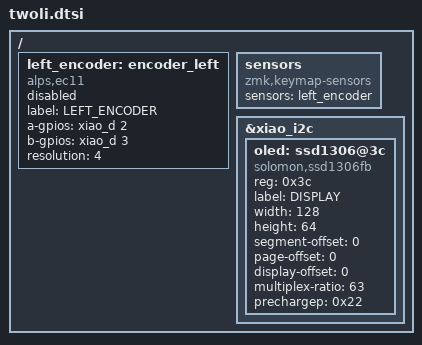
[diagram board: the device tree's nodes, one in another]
/ {

    left_encoder: encoder_left {
		compatible = "alps,ec11";
		label = "LEFT_ENCODER";
		a-gpios = <&xiao_d 2 (GPIO_ACTIVE_HIGH | GPIO_PULL_UP)>;
		b-gpios = <&xiao_d 3 (GPIO_ACTIVE_HIGH | GPIO_PULL_UP)>;
		resolution = <4>;
		status = "enabled";
	};

	sensors {
		compatible = "zmk,keymap-sensors";
		sensors = <&left_encoder>;
	};

    
    &xiao_i2c {
        status = "okay";

        oled: ssd1306@3c {
            compatible = "solomon,ssd1306fb";
            reg = <0x3c>;
            label = "DISPLAY";
            width = <128>;
            height = <64>;
            segment-offset = <0>;
            page-offset = <0>;
            display-offset = <0>;
            multiplex-ratio = <63>;
            //segment-remap;
            //com-invdir;
            //com-sequential;
            prechargep = <0x22>;
        };
    };

};
